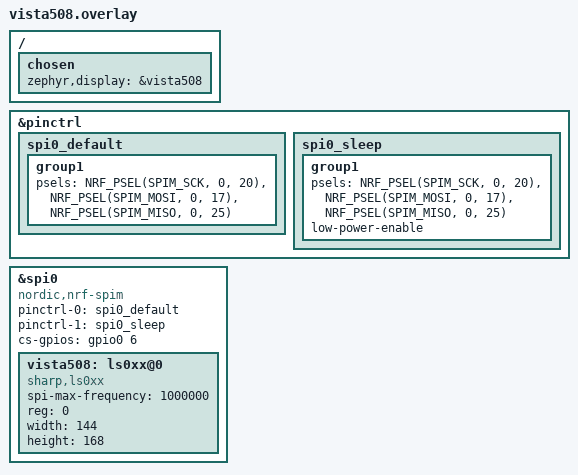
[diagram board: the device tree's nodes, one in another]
/*
 * Copyright (c) 2022 The ZMK Contributors
 *
 * SPDX-License-Identifier: MIT
 *
 * Kept as close as possible to LXF-YZP/zmk-config-rolio@tps65's vista508.overlay
 * for easy A/B debugging. The eyelash_corne is NOT a nice_nano, so three rolio
 * lines are changed/removed and each is noted inline:
 *   - CS: rolio uses `<&pro_micro 1>`; on the eyelash that same physical pin is
 *     `<&gpio0 6>` (P0.06).
 *   - rolio disables `&pro_micro_i2c`, `&oled`, `&tps43` on the display half.
 *     The eyelash has no `pro_micro_i2c`/`oled` label at all, and its `tps43`
 *     node exists only on the RIGHT overlay, so those three lines are omitted
 *     (they would be undefined-label errors here). SPI0-vs-touchpad arbitration
 *     is instead handled on the RIGHT half (eyelash_corne_right.dts disables
 *     SPI0 and brings up I2C0 on P0.17/P0.20).
 */

// Enable SPI for the Vista508 MIP display.
&pinctrl {
    spi0_default: spi0_default {
        group1 {
            psels = <NRF_PSEL(SPIM_SCK, 0, 20)>,
                <NRF_PSEL(SPIM_MOSI, 0, 17)>,
                <NRF_PSEL(SPIM_MISO, 0, 25)>;
        };
    };

    spi0_sleep: spi0_sleep {
        group1 {
            psels = <NRF_PSEL(SPIM_SCK, 0, 20)>,
                <NRF_PSEL(SPIM_MOSI, 0, 17)>,
                <NRF_PSEL(SPIM_MISO, 0, 25)>;
            low-power-enable;
        };
    };
};

nice_view_spi: &spi0 {
    compatible = "nordic,nrf-spim";
    pinctrl-0 = <&spi0_default>;
    pinctrl-1 = <&spi0_sleep>;
    pinctrl-names = "default", "sleep";
    cs-gpios = <&gpio0 6 GPIO_ACTIVE_HIGH>;   // rolio: <&pro_micro 1> (== P0.06 == gpio0 6)
};

// rolio also disables &pro_micro_i2c, &oled and &tps43 here -- omitted: those
// labels do not exist on the eyelash_corne LEFT half (see header note).

&nice_view_spi {
    status = "okay";
    vista508: ls0xx@0 {
        compatible = "sharp,ls0xx";
        spi-max-frequency = <1000000>;
        reg = <0>;
        width = <144>;
        height = <168>;
    };
};

/ {
    chosen {
        zephyr,display = &vista508;
    };
};
